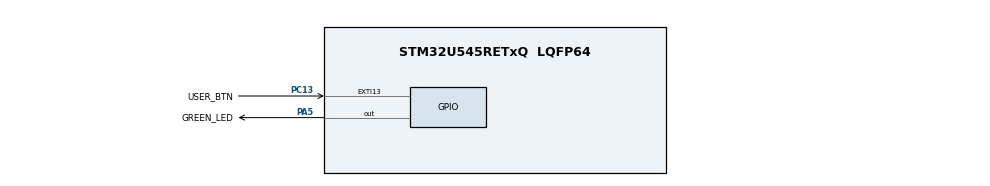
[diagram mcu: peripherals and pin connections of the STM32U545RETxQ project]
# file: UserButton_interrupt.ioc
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CORTEX_M33_NS.userName=CORTEX_M33
Mcu.Family=STM32U5
Mcu.Name=STM32U545RETxQ
Mcu.Package=LQFP64
NVIC.EXTI13_IRQn=true\:2\:0\:true\:false\:true\:true\:true\:true
NVIC.PriorityGroup=NVIC_PRIORITYGROUP_4
PA5.GPIO_Label=GREEN_LED
PA5.Signal=GPIO_Output
PC13.GPIO_Label=USER_BTN
PC13.GPIO_ModeDefaultEXTI=GPIO_MODE_IT_RISING
PC13.GPIO_PuPd=GPIO_PULLDOWN
PC13.Signal=GPXTI13
PWR.PowerMode=PWR_SMPS_SUPPLY
ProjectManager.HeapSize=0x200
ProjectManager.StackSize=0x400
ProjectManager.TargetToolchain=STM32CubeIDE
RCC.ADCFreq_Value=16000000
RCC.DACCLockSelectionVirtual=RCC_DAC1CLKSOURCE_LSI
RCC.DACCLockSelectionVirtualString=RCC_DAC1CLKSOURCE_LSI
RCC.EPOD_VALUE=4000000
RCC.HSE_VALUE=16000000
RCC.HSI48_VALUE=48000000
RCC.HSI_VALUE=16000000
RCC.LSE_VALUE=32768
RCC.LSIDIV_VALUE=32000
RCC.MSI_VALUE=4000000
RCC.USBFreq_Value=48000000
RCC.VCOOutputFreq_Value=516000000
VP_ICACHE_VS_ICACHE.Mode=DirectMappedCache
VP_LPBAMQUEUE_VS_QUEUE.Mode=QUEUEMODE
VP_MEMORYMAP_VS_MEMORYMAP.Mode=CurAppReg
VP_NUCLEO-U545RE-Q_VS_BSP_COMMON.Mode=COMMON
VP_PWR_VS_LPOM.Mode=PowerOptimisation
VP_PWR_VS_SECSignals.Mode=Security/Privilege
board=NUCLEO-U545RE-Q

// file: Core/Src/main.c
/* USER CODE BEGIN Header */
/**
  ******************************************************************************
  * @file           : main.c
  * @brief          : Main program body
  ******************************************************************************
  * @attention
  *
  * Copyright (c) 2026 STMicroelectronics.
  * All rights reserved.
  *
  * This software is licensed under terms that can be found in the LICENSE file
  * in the root directory of this software component.
  * If no LICENSE file comes with this software, it is provided AS-IS.
  *
  ******************************************************************************
  */
/* USER CODE END Header */
#include "main.h"

void SystemClock_Config(void);
static void SystemPower_Config(void);
static void MX_GPIO_Init(void);
static void MX_ICACHE_Init(void);

/* USER CODE BEGIN 0 */
void HAL_GPIO_EXTI_Rising_Callback(uint16_t GPIO_Pin) {
   if (GPIO_Pin == GPIO_PIN_13) {
       // It changes the GREEN led statuHAL_GPIO_EXTI_Rising_Callbacks
       HAL_GPIO_TogglePin(GPIOA, GPIO_PIN_5);
   }
}

/* USER CODE END 0 */

int main(void)
{

  /* MCU Configuration--------------------------------------------------------*/

  /* Reset of all peripherals, Initializes the Flash interface and the Systick. */
  HAL_Init();

  /* Configure the System Power */
  SystemPower_Config();

  /* Configure the system clock */
  SystemClock_Config();

  /* Initialize all configured peripherals */
  MX_GPIO_Init();
  MX_ICACHE_Init();

  /* Infinite loop */
  while (1)
  {

  }
}

void SystemClock_Config(void)
{
  RCC_OscInitTypeDef RCC_OscInitStruct = {0};
  RCC_ClkInitTypeDef RCC_ClkInitStruct = {0};

  /** Configure the main internal regulator output voltage
  */
  if (HAL_PWREx_ControlVoltageScaling(PWR_REGULATOR_VOLTAGE_SCALE4) != HAL_OK)
  {
    Error_Handler();
  }

  /** Initializes the CPU, AHB and APB buses clocks
  */
  RCC_OscInitStruct.OscillatorType = RCC_OSCILLATORTYPE_MSI;
  RCC_OscInitStruct.MSIState = RCC_MSI_ON;
  RCC_OscInitStruct.MSICalibrationValue = RCC_MSICALIBRATION_DEFAULT;
  RCC_OscInitStruct.MSIClockRange = RCC_MSIRANGE_4;
  RCC_OscInitStruct.PLL.PLLState = RCC_PLL_NONE;
  if (HAL_RCC_OscConfig(&RCC_OscInitStruct) != HAL_OK)
  {
    Error_Handler();
  }

  /** Initializes the CPU, AHB and APB buses clocks
  */
  RCC_ClkInitStruct.ClockType = RCC_CLOCKTYPE_HCLK|RCC_CLOCKTYPE_SYSCLK
                              |RCC_CLOCKTYPE_PCLK1|RCC_CLOCKTYPE_PCLK2
                              |RCC_CLOCKTYPE_PCLK3;
  RCC_ClkInitStruct.SYSCLKSource = RCC_SYSCLKSOURCE_MSI;
  RCC_ClkInitStruct.AHBCLKDivider = RCC_SYSCLK_DIV1;
  RCC_ClkInitStruct.APB1CLKDivider = RCC_HCLK_DIV1;
  RCC_ClkInitStruct.APB2CLKDivider = RCC_HCLK_DIV1;
  RCC_ClkInitStruct.APB3CLKDivider = RCC_HCLK_DIV1;

  if (HAL_RCC_ClockConfig(&RCC_ClkInitStruct, FLASH_LATENCY_0) != HAL_OK)
  {
    Error_Handler();
  }
}

/**
  * @brief Power Configuration
  * @retval None
  */
static void SystemPower_Config(void)
{

  /*
   * Switch to SMPS regulator instead of LDO
   */
  if (HAL_PWREx_ConfigSupply(PWR_SMPS_SUPPLY) != HAL_OK)
  {
    Error_Handler();
  }
}

static void MX_ICACHE_Init(void)
{

  /** Enable instruction cache in 1-way (direct mapped cache)
  */
  if (HAL_ICACHE_ConfigAssociativityMode(ICACHE_1WAY) != HAL_OK)
  {
    Error_Handler();
  }
  if (HAL_ICACHE_Enable() != HAL_OK)
  {
    Error_Handler();
  }

}

static void MX_GPIO_Init(void)
{
  GPIO_InitTypeDef GPIO_InitStruct = {0};

  /* GPIO Ports Clock Enable */
  __HAL_RCC_GPIOC_CLK_ENABLE();
  __HAL_RCC_GPIOA_CLK_ENABLE();

  /*Configure GPIO pin Output Level */
  HAL_GPIO_WritePin(GREEN_LED_GPIO_Port, GREEN_LED_Pin, GPIO_PIN_RESET);

  /*Configure GPIO pin : USER_BTN_Pin */
  GPIO_InitStruct.Pin = USER_BTN_Pin;
  GPIO_InitStruct.Mode = GPIO_MODE_IT_RISING;
  GPIO_InitStruct.Pull = GPIO_PULLDOWN;
  HAL_GPIO_Init(USER_BTN_GPIO_Port, &GPIO_InitStruct);

  /*Configure GPIO pin : GREEN_LED_Pin */
  GPIO_InitStruct.Pin = GREEN_LED_Pin;
  GPIO_InitStruct.Mode = GPIO_MODE_OUTPUT_PP;
  GPIO_InitStruct.Pull = GPIO_NOPULL;
  GPIO_InitStruct.Speed = GPIO_SPEED_FREQ_LOW;
  HAL_GPIO_Init(GREEN_LED_GPIO_Port, &GPIO_InitStruct);

  /* EXTI interrupt init*/
  HAL_NVIC_SetPriority(EXTI13_IRQn, 2, 0);
  HAL_NVIC_EnableIRQ(EXTI13_IRQn);

}

void Error_Handler(void)
{
  __disable_irq();
  while (1)
  {
  }
}
